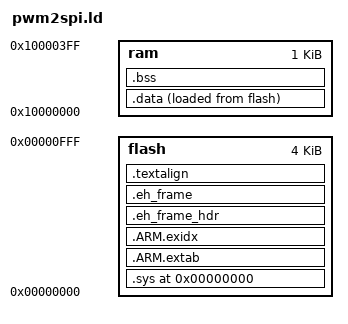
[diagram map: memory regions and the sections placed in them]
MEMORY
{
    flash : org = 0x00000000, len = 4k
    ram : org = 0x10000000, len = 1k
}

__ram_start__           = ORIGIN(ram);
__ram_size__            = 1k;
__ram_end__             = __ram_start__ + __ram_size__;

SECTIONS
{
    . = 0;

    .sys : ALIGN(4) SUBALIGN(4)
    {
	_sys = .;
	KEEP(*(.vectors))
	. = 0x2fc;
	KEEP(*(.crp))
	. = 0x300;
    	_text = .;
        *(.text)
        *(.text.*)
        *(.rodata)
        *(.rodata.*)
        *(.glue_7t)
        *(.glue_7)
        *(.gcc*)
	. = ALIGN(8);
    } > flash

    .ARM.extab : {*(.ARM.extab* .gnu.linkonce.armextab.*)} > flash

    .ARM.exidx : {
        PROVIDE(__exidx_start = .);
        *(.ARM.exidx* .gnu.linkonce.armexidx.*)
        PROVIDE(__exidx_end = .);
     } > flash

    .eh_frame_hdr : {*(.eh_frame_hdr)} > flash

    .eh_frame : ONLY_IF_RO {*(.eh_frame)} > flash

    .textalign : ONLY_IF_RO { . = ALIGN(8); } > flash

    _etext = .;
    _textdata = _etext;

    .data :
    {
        . = ALIGN(4);
        PROVIDE(_data = .);
        *(.data)
        . = ALIGN(4);
        *(.data.*)
        . = ALIGN(4);
        *(.ramtext)
        . = ALIGN(4);
        PROVIDE(_edata = .);
    } > ram AT > flash

    .bss :
    {
        . = ALIGN(4);
        PROVIDE(_bss_start = .);
        *(.bss)
        . = ALIGN(4);
        *(.bss.*)
        . = ALIGN(4);
        *(COMMON)
        . = ALIGN(4);
        PROVIDE(_bss_end = .);
    } > ram

    PROVIDE(end = .);
    _end            = .;
}
